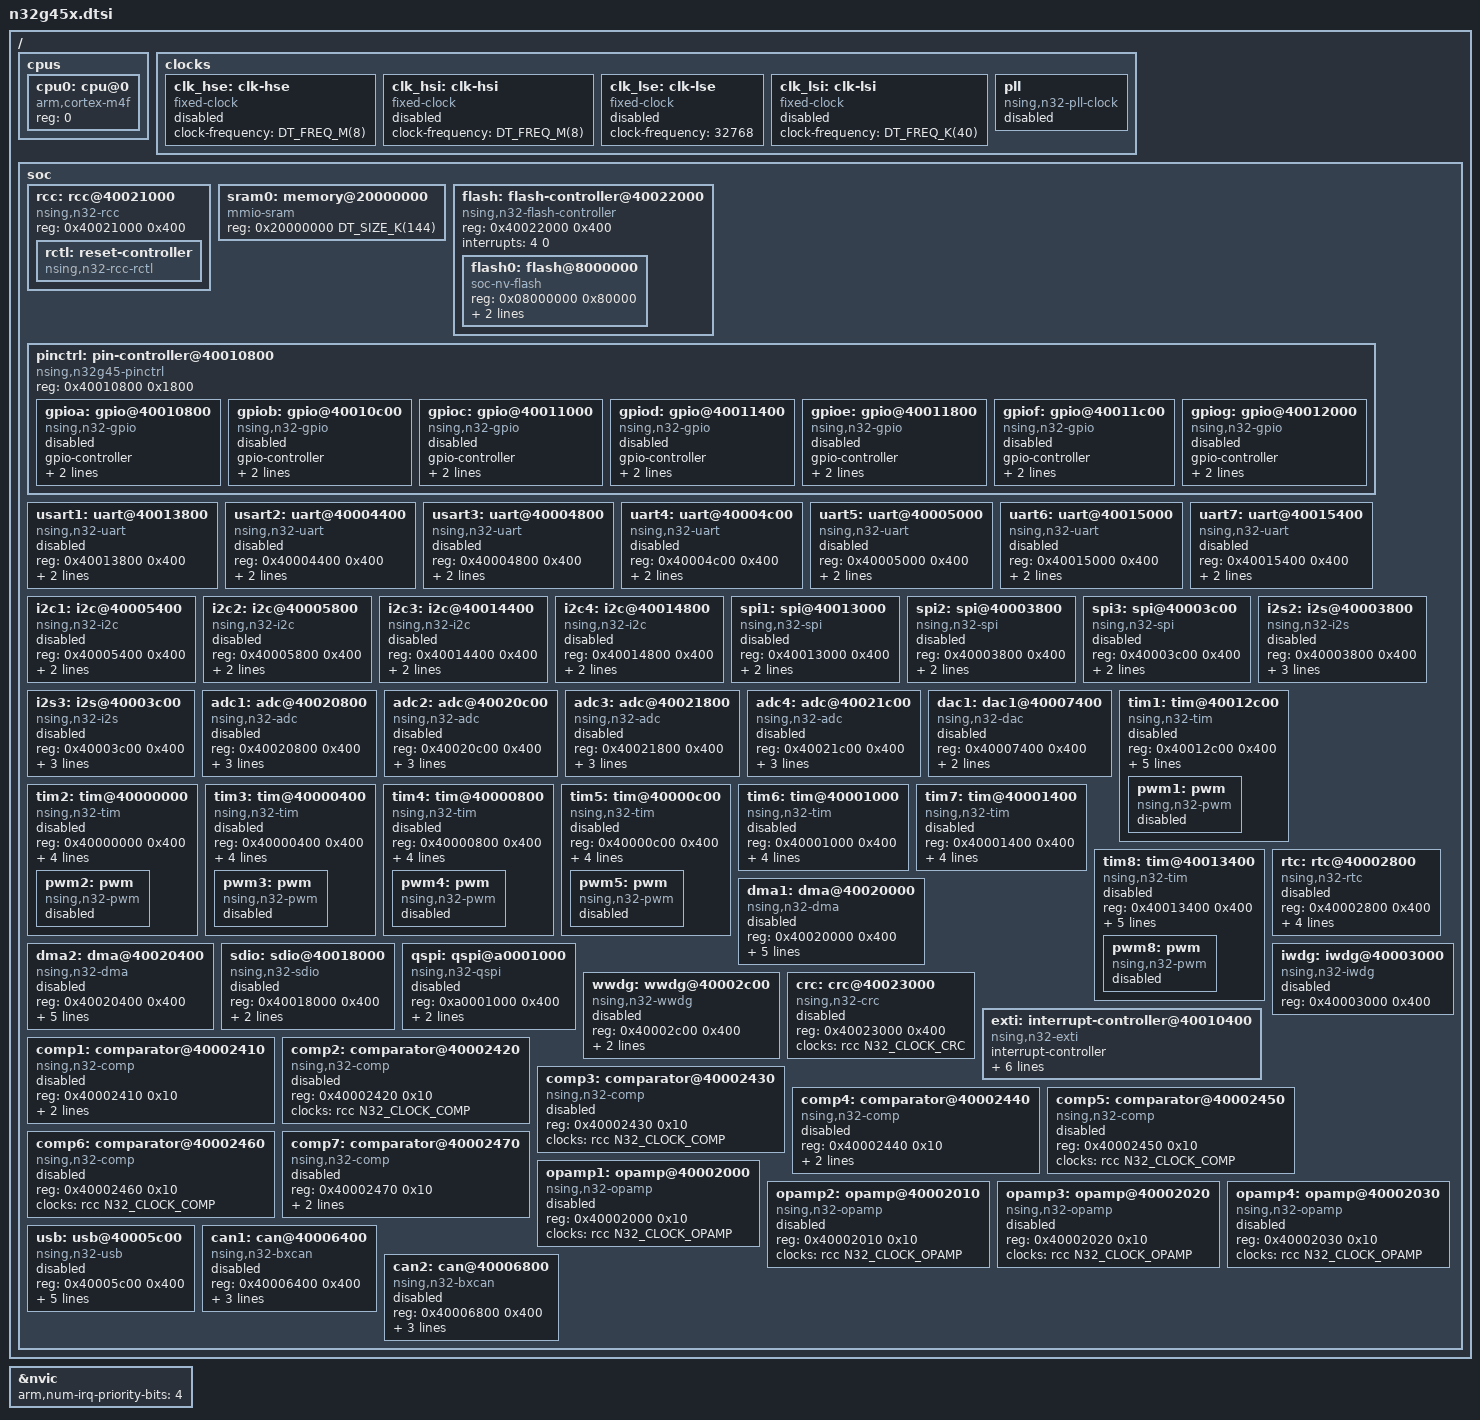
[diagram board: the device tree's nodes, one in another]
/*
 * Copyright (c) 2024 Nations Technologies
 * SPDX-License-Identifier: Apache-2.0
 *
 * N32G45x SoC devicetree, written from the peripheral definitions in
 * modules/hal/nsing.
 *
 * The base addresses and interrupt numbers come from the HAL's n32g45x.h,
 * the clock bits from n32_clock.h. The following peripherals are described:
 * I2C1-4, SPI1-3, ADC1-4, TIM1-8, DMA1-2, DAC, CAN1-2, RTC, SDIO, DVP, ETH,
 * QSPI, IWDG, WWDG, BKP, PWR, CRC, EXTI, COMP, OPAMP, TSC, RCC, FLASH, SRAM,
 * GPIOA-G and the USART/UART instances.
 *
 * TIM, DMA, RTC, SDIO, DVP, ETH, QSPI, IWDG, WWDG, BKP, PWR, CRC, EXTI and
 * TSC have no Zephyr driver yet, so their nodes are kept in block comments
 * until one exists. The COMP (7 instances) and OPAMP (4 instances) drivers
 * live in drivers/comparator and drivers/opamp.
 */

#include <mem.h>
#include <freq.h>
#include <arm/armv7-m.dtsi>
#include <zephyr/dt-bindings/gpio/gpio.h>
#include <zephyr/dt-bindings/i2c/i2c.h>
#include <zephyr/dt-bindings/clock/n32_clock.h>
#include <zephyr/dt-bindings/dma/n32_dma.h>
#include <zephyr/dt-bindings/reset/n32g45x-reset.h>

/ {

	cpus {
		#address-cells = <1>;
		#size-cells = <0>;

		cpu0: cpu@0 {
			device_type = "cpu";
			compatible = "arm,cortex-m4f";
			reg = <0>;
		};
	};

	clocks {
		clk_hse: clk-hse {
			#clock-cells = <0>;
			compatible = "fixed-clock";
			clock-frequency = <DT_FREQ_M(8)>;
			status = "disabled";
		};

		clk_hsi: clk-hsi {
			#clock-cells = <0>;
			compatible = "fixed-clock";
			clock-frequency = <DT_FREQ_M(8)>;
			status = "disabled";
		};

		clk_lse: clk-lse {
			#clock-cells = <0>;
			compatible = "fixed-clock";
			clock-frequency = <32768>;
			status = "disabled";
		};

		clk_lsi: clk-lsi {
			#clock-cells = <0>;
			compatible = "fixed-clock";
			clock-frequency = <DT_FREQ_K(40)>;
			status = "disabled";
		};

		pll: pll {
			#clock-cells = <0>;
			compatible = "nsing,n32-pll-clock";
			status = "disabled";
		};
	};

	soc {
		rcc: rcc@40021000 {
			compatible = "nsing,n32-rcc";
			#clock-cells = <1>;
			reg = <0x40021000 0x400>;

			rctl: reset-controller {
				compatible = "nsing,n32-rcc-rctl";
				#reset-cells = <1>;
			};
		};

		sram0: memory@20000000 {
			compatible = "mmio-sram";
			reg = <0x20000000 DT_SIZE_K(144)>;
		};

		flash: flash-controller@40022000 {
			compatible = "nsing,n32-flash-controller";
			reg = <0x40022000 0x400>;
			interrupts = <4 0>;
			#address-cells = <1>;
			#size-cells = <1>;

			flash0: flash@8000000 {
				compatible = "soc-nv-flash";
				reg = <0x08000000 0x80000>;
				write-block-size = <4>;
				erase-block-size = <0x800>;
			};
		};

		pinctrl: pin-controller@40010800 {
			compatible = "nsing,n32g45-pinctrl";
			reg = <0x40010800 0x1800>;
			#address-cells = <1>;
			#size-cells = <1>;

			gpioa: gpio@40010800 {
				compatible = "nsing,n32-gpio";
				gpio-controller;
				#gpio-cells = <2>;
				reg = <0x40010800 0x400>;
				clocks = <&rcc N32_CLOCK_GPIOA>;
				status = "disabled";
			};

			gpiob: gpio@40010c00 {
				compatible = "nsing,n32-gpio";
				gpio-controller;
				#gpio-cells = <2>;
				reg = <0x40010c00 0x400>;
				clocks = <&rcc N32_CLOCK_GPIOB>;
				status = "disabled";
			};

			gpioc: gpio@40011000 {
				compatible = "nsing,n32-gpio";
				gpio-controller;
				#gpio-cells = <2>;
				reg = <0x40011000 0x400>;
				clocks = <&rcc N32_CLOCK_GPIOC>;
				status = "disabled";
			};

			gpiod: gpio@40011400 {
				compatible = "nsing,n32-gpio";
				gpio-controller;
				#gpio-cells = <2>;
				reg = <0x40011400 0x400>;
				clocks = <&rcc N32_CLOCK_GPIOD>;
				status = "disabled";
			};

			gpioe: gpio@40011800 {
				compatible = "nsing,n32-gpio";
				gpio-controller;
				#gpio-cells = <2>;
				reg = <0x40011800 0x400>;
				clocks = <&rcc N32_CLOCK_GPIOE>;
				status = "disabled";
			};

			gpiof: gpio@40011c00 {
				compatible = "nsing,n32-gpio";
				gpio-controller;
				#gpio-cells = <2>;
				reg = <0x40011c00 0x400>;
				clocks = <&rcc N32_CLOCK_GPIOF>;
				status = "disabled";
			};

			gpiog: gpio@40012000 {
				compatible = "nsing,n32-gpio";
				gpio-controller;
				#gpio-cells = <2>;
				reg = <0x40012000 0x400>;
				clocks = <&rcc N32_CLOCK_GPIOG>;
				status = "disabled";
			};
		};

		usart1: uart@40013800 {
			compatible = "nsing,n32-uart";
			reg = <0x40013800 0x400>;
			clocks = <&rcc N32_CLOCK_USART1>;
			interrupts = <37 0>;
			status = "disabled";
		};

		usart2: uart@40004400 {
			compatible = "nsing,n32-uart";
			reg = <0x40004400 0x400>;
			clocks = <&rcc N32_CLOCK_USART2>;
			interrupts = <38 0>;
			status = "disabled";
		};

		usart3: uart@40004800 {
			compatible = "nsing,n32-uart";
			reg = <0x40004800 0x400>;
			clocks = <&rcc N32_CLOCK_USART3>;
			interrupts = <39 0>;
			status = "disabled";
		};

		uart4: uart@40004c00 {
			compatible = "nsing,n32-uart";
			reg = <0x40004c00 0x400>;
			clocks = <&rcc N32_CLOCK_UART4>;
			interrupts = <52 0>;
			status = "disabled";
		};

		uart5: uart@40005000 {
			compatible = "nsing,n32-uart";
			reg = <0x40005000 0x400>;
			clocks = <&rcc N32_CLOCK_UART5>;
			interrupts = <53 0>;
			status = "disabled";
		};

		uart6: uart@40015000 {
			compatible = "nsing,n32-uart";
			reg = <0x40015000 0x400>;
			clocks = <&rcc N32_CLOCK_UART6>;
			interrupts = <74 0>;
			status = "disabled";
		};

		uart7: uart@40015400 {
			compatible = "nsing,n32-uart";
			reg = <0x40015400 0x400>;
			clocks = <&rcc N32_CLOCK_UART7>;
			interrupts = <75 0>;
			status = "disabled";
		};

		i2c1: i2c@40005400 {
			compatible = "nsing,n32-i2c";
			#address-cells = <1>;
			#size-cells = <0>;
			reg = <0x40005400 0x400>;
			clocks = <&rcc N32_CLOCK_I2C1>;
			interrupts = <31 0>, <32 0>;
			interrupt-names = "event", "error";
			status = "disabled";
		};

		i2c2: i2c@40005800 {
			compatible = "nsing,n32-i2c";
			#address-cells = <1>;
			#size-cells = <0>;
			reg = <0x40005800 0x400>;
			clocks = <&rcc N32_CLOCK_I2C2>;
			interrupts = <33 0>, <34 0>;
			interrupt-names = "event", "error";
			status = "disabled";
		};

		i2c3: i2c@40014400 {
			compatible = "nsing,n32-i2c";
			#address-cells = <1>;
			#size-cells = <0>;
			reg = <0x40014400 0x400>;
			clocks = <&rcc N32_CLOCK_I2C3>;
			interrupts = <70 0>, <71 0>;
			interrupt-names = "event", "error";
			status = "disabled";
		};

		i2c4: i2c@40014800 {
			compatible = "nsing,n32-i2c";
			#address-cells = <1>;
			#size-cells = <0>;
			reg = <0x40014800 0x400>;
			clocks = <&rcc N32_CLOCK_I2C4>;
			interrupts = <72 0>, <73 0>;
			interrupt-names = "event", "error";
			status = "disabled";
		};

		spi1: spi@40013000 {
			compatible = "nsing,n32-spi";
			#address-cells = <1>;
			#size-cells = <0>;
			reg = <0x40013000 0x400>;
			clocks = <&rcc N32_CLOCK_SPI1>;
			interrupts = <35 5>;
			status = "disabled";
		};

		spi2: spi@40003800 {
			compatible = "nsing,n32-spi";
			#address-cells = <1>;
			#size-cells = <0>;
			reg = <0x40003800 0x400>;
			clocks = <&rcc N32_CLOCK_SPI2>;
			interrupts = <36 0>;
			status = "disabled";
		};

		spi3: spi@40003c00 {
			compatible = "nsing,n32-spi";
			#address-cells = <1>;
			#size-cells = <0>;
			reg = <0x40003c00 0x400>;
			clocks = <&rcc N32_CLOCK_SPI3>;
			interrupts = <51 0>;
			status = "disabled";
		};

		/*
		 * The I2S blocks are the same hardware as spi2/spi3 in I2S mode,
		 * so these deliberately share their unit addresses: a board
		 * enables one node of a given instance or the other, never both.
		 * SPI1 has no I2S mode.
		 *
		 * The DMA request cell is 0, which leaves each channel on its
		 * hardwired mapping -- what the vendor examples rely on. The
		 * channel cell is 0-based, so dma1 channels 3 and 4 are the
		 * vendor's DMA1_CH4 and DMA1_CH5.
		 */
		i2s2: i2s@40003800 {
			compatible = "nsing,n32-i2s";
			reg = <0x40003800 0x400>;
			clocks = <&rcc N32_CLOCK_SPI2>;
			interrupts = <36 0>;
			dmas = <&dma1 3 0 0>, <&dma1 4 0 0>;
			dma-names = "rx", "tx";
			status = "disabled";
		};

		i2s3: i2s@40003c00 {
			compatible = "nsing,n32-i2s";
			reg = <0x40003c00 0x400>;
			clocks = <&rcc N32_CLOCK_SPI3>;
			interrupts = <51 0>;
			dmas = <&dma2 0 0 0>, <&dma2 1 0 0>;
			dma-names = "rx", "tx";
			status = "disabled";
		};

		adc1: adc@40020800 {
			compatible = "nsing,n32-adc";
			reg = <0x40020800 0x400>;
			clocks = <&rcc N32_CLOCK_ADC1>;
			interrupts = <18 0>;
			#io-channel-cells = <1>;
			channels = <16>;
			status = "disabled";
		};

		adc2: adc@40020c00 {
			compatible = "nsing,n32-adc";
			reg = <0x40020c00 0x400>;
			clocks = <&rcc N32_CLOCK_ADC2>;
			interrupts = <18 0>;
			#io-channel-cells = <1>;
			channels = <16>;
			status = "disabled";
		};

		adc3: adc@40021800 {
			compatible = "nsing,n32-adc";
			reg = <0x40021800 0x400>;
			clocks = <&rcc N32_CLOCK_ADC3>;
			interrupts = <47 0>;
			#io-channel-cells = <1>;
			channels = <16>;
			status = "disabled";
		};

		adc4: adc@40021c00 {
			compatible = "nsing,n32-adc";
			reg = <0x40021c00 0x400>;
			clocks = <&rcc N32_CLOCK_ADC4>;
			interrupts = <47 0>;
			#io-channel-cells = <1>;
			channels = <16>;
			status = "disabled";
		};

		dac1: dac1@40007400 {
			compatible = "nsing,n32-dac";
			reg = <0x40007400 0x400>;
			clocks = <&rcc N32_CLOCK_DAC>;
			num-channels = <2>;
			#io-channel-cells = <1>;
			status = "disabled";

		};

		/* TIM1 and TIM8 are advanced timers; TIM2-TIM5 are general-purpose. */
		tim1: tim@40012c00 {
			compatible = "nsing,n32-tim";
			reg = <0x40012c00 0x400>;
			clocks = <&rcc N32_CLOCK_TIM1>;
			interrupts = <25 0>, <24 0>, <26 0>, <27 0>;
			interrupt-names = "up", "brk", "trg_com", "cc";
			prescaler = <0>;
			channels = <4>;
			advanced;
			status = "disabled";
			pwm1: pwm {
				compatible = "nsing,n32-pwm";
				#pwm-cells = <3>;
				status = "disabled";
			};
		};
		tim2: tim@40000000 {
			compatible = "nsing,n32-tim";
			reg = <0x40000000 0x400>;
			clocks = <&rcc N32_CLOCK_TIM2>;
			interrupts = <28 0>;
			prescaler = <0>;
			channels = <4>;
			status = "disabled";
			pwm2: pwm {
				compatible = "nsing,n32-pwm";
				#pwm-cells = <3>;
				status = "disabled";
			};
		};
		tim3: tim@40000400 {
			compatible = "nsing,n32-tim";
			reg = <0x40000400 0x400>;
			clocks = <&rcc N32_CLOCK_TIM3>;
			interrupts = <29 0>;
			prescaler = <0>;
			channels = <4>;
			status = "disabled";
			pwm3: pwm {
				compatible = "nsing,n32-pwm";
				#pwm-cells = <3>;
				status = "disabled";
			};
		};
		tim4: tim@40000800 {
			compatible = "nsing,n32-tim";
			reg = <0x40000800 0x400>;
			clocks = <&rcc N32_CLOCK_TIM4>;
			interrupts = <30 0>;
			prescaler = <0>;
			channels = <4>;
			status = "disabled";
			pwm4: pwm {
				compatible = "nsing,n32-pwm";
				#pwm-cells = <3>;
				status = "disabled";
			};
		};
		tim5: tim@40000c00 {
			compatible = "nsing,n32-tim";
			reg = <0x40000c00 0x400>;
			clocks = <&rcc N32_CLOCK_TIM5>;
			interrupts = <50 0>;
			prescaler = <0>;
			channels = <4>;
			status = "disabled";
			pwm5: pwm {
				compatible = "nsing,n32-pwm";
				#pwm-cells = <3>;
				status = "disabled";
			};
		};
		tim6: tim@40001000 {
			compatible = "nsing,n32-tim";
			reg = <0x40001000 0x400>;
			clocks = <&rcc N32_CLOCK_TIM6>;
			interrupts = <54 0>;
			prescaler = <0>;
			channels = <0>;
			status = "disabled";
		};
		tim7: tim@40001400 {
			compatible = "nsing,n32-tim";
			reg = <0x40001400 0x400>;
			clocks = <&rcc N32_CLOCK_TIM7>;
			interrupts = <55 0>;
			prescaler = <0>;
			channels = <0>;
			status = "disabled";
		};
		tim8: tim@40013400 {
			compatible = "nsing,n32-tim";
			reg = <0x40013400 0x400>;
			clocks = <&rcc N32_CLOCK_TIM8>;
			interrupts = <44 0>, <43 0>, <45 0>, <46 0>;
			interrupt-names = "up", "brk", "trg_com", "cc";
			prescaler = <0>;
			channels = <4>;
			advanced;
			status = "disabled";
			pwm8: pwm {
				compatible = "nsing,n32-pwm";
				#pwm-cells = <3>;
				status = "disabled";
			};
		};

		/* Interrupt order is channel order: the driver connects IRQ_BY_IDX(n)
		 * to channel n.
		 */
		dma1: dma@40020000 {
			compatible = "nsing,n32-dma";
			reg = <0x40020000 0x400>;
			clocks = <&rcc N32_CLOCK_DMA1>;
			interrupts = <11 0>, <12 0>, <13 0>, <14 0>, <15 0>, <16 0>, <17 0>, <76 0>;
			#dma-cells = <3>;
			dma-channels = <8>;
			nsing,mem2mem;
			status = "disabled";
		};

		dma2: dma@40020400 {
			compatible = "nsing,n32-dma";
			reg = <0x40020400 0x400>;
			clocks = <&rcc N32_CLOCK_DMA2>;
			interrupts = <56 0>, <57 0>, <58 0>, <59 0>, <60 0>, <68 0>, <69 0>, <77 0>;
			#dma-cells = <3>;
			dma-channels = <8>;
			nsing,mem2mem;
			status = "disabled";
		};

		rtc: rtc@40002800 {
			compatible = "nsing,n32-rtc";
			reg = <0x40002800 0x400>;
			interrupts = <41 0>;
			/* Backup-domain access gates: BKP + PWR on APB1. */
			clocks = <&rcc N32_CLOCK_BKP>, <&rcc N32_CLOCK_PWR>;
			alarms-count = <2>;
			alrm-exti-line = <17>;
			status = "disabled";
		};

	/* ---- Other peripherals, each still needs a binding ---- */

		sdio: sdio@40018000 {
			compatible = "nsing,n32-sdio";
			reg = <0x40018000 0x400>;
			clocks = <&rcc N32_CLOCK_SDIO>;
			interrupts = <49 0>;
			status = "disabled";
		};

/*
 *         dvp: dvp@40014c00 {
 *             compatible = "nsing,n32-dvp";
 *             reg = <0x40014c00 0x400>;
 *             clocks = <&rcc N32_CLOCK_DVP>;
 *             interrupts = <78 0>;
 *             status = "disabled";
 *         };
 */

/*
 *         eth: eth@40028000 {
 *             compatible = "nsing,n32-eth";
 *             reg = <0x40028000 0x400>;
 *             clocks = <&rcc N32_CLOCK_ETH>;
 *             interrupts = <61 0>;
 *             status = "disabled";
 *         };
 */

		/*
		 * The transmit channel only. The driver hands a packet that is
		 * longer than the FIFO to it, because a frame pushed by the CPU
		 * costs more time than one the core shifts; the receive side
		 * needs no channel.
		 *
		 * The request cell is not optional here, unlike the SPI/I2S nodes
		 * above whose channels do have a hardwired request. Nothing on
		 * this part drives a DMA request from the QSPI unless it is
		 * remapped, so a zero in that cell leaves the channel triggered by
		 * whatever else its default mapping carries -- which is what the
		 * vendor examples avoid by asking for the same code explicitly.
		 * The channel is then a channel like any other: CHSEL and the
		 * controller wide CHMAPEN bit are what route the request, so seven
		 * is only a nod to the vendor, which transmits on DMA2_CH7.
		 */
		qspi: qspi@a0001000 {
			compatible = "nsing,n32-qspi";
			reg = <0xa0001000 0x400>;
			clocks = <&rcc N32_CLOCK_QSPI>;
			dmas = <&dma2 7 N32_DMA2_REQ_QSPI_TX 0>;
			dma-names = "tx";
			#address-cells = <1>;
			#size-cells = <0>;
			status = "disabled";
		};

		iwdg: iwdg@40003000 {
			compatible = "nsing,n32-iwdg";
			reg = <0x40003000 0x400>;
			status = "disabled";
		};

		wwdg: wwdg@40002c00 {
			compatible = "nsing,n32-wwdg";
			reg = <0x40002c00 0x400>;
			clocks = <&rcc N32_CLOCK_WWDG>;
			interrupts = <0 0>;
			status = "disabled";
		};

/*
 *         bkp: bkp@40006c00 {
 *             compatible = "nsing,n32-bkp";
 *             reg = <0x40006c00 0x400>;
 *             clocks = <&rcc N32_CLOCK_BKP>;
 *             status = "disabled";
 *         };
 */

/*
 *         pwr: pwr@40007000 {
 *             compatible = "nsing,n32-pwr";
 *             reg = <0x40007000 0x400>;
 *             clocks = <&rcc N32_CLOCK_PWR>;
 *             status = "disabled";
 *         };
 */

	crc: crc@40023000 {
		compatible = "nsing,n32-crc";
		reg = <0x40023000 0x400>;
		clocks = <&rcc N32_CLOCK_CRC>;
		status = "disabled";
	};

		/* EXTI shares the AFIO clock and hangs off APB2. */
		exti: interrupt-controller@40010400 {
			compatible = "nsing,n32-exti";
			interrupt-controller;
			#interrupt-cells = <1>;
			reg = <0x40010400 0x400>;
			num-lines = <16>;
			interrupts = <6 0>, <7 0>, <8 0>, <9 0>,
				     <10 0>, <23 0>, <40 0>;
			interrupt-names = "line0", "line1", "line2", "line3",
					  "line4", "line5-9", "line10-15";
			line-ranges = <0 1>, <1 1>, <2 1>, <3 1>,
				      <4 1>, <5 5>, <10 6>;
		};

		/* One device node per N32G45x COMP / OPAMP instance, for the generic
		 * Zephyr comparator and opamp subsystems. Base addresses: COMP at
		 * 0x40002400 (each channel's CTRL at +0x10), OPAMP at 0x40002000
		 * (each channel's CS at +0x10). The COMP interrupt lines are shared:
		 * COMP1/2/3 -> 82, COMP4/5/6 -> 83, COMP7 -> 84. Only one comparator
		 * per group can use the interrupt callback at a time, so interrupts
		 * are declared on the first instance of each group only.
		 */
		comp1: comparator@40002410 {
			compatible = "nsing,n32-comp";
			reg = <0x40002410 0x10>;
			clocks = <&rcc N32_CLOCK_COMP>;
			interrupts = <82 0>;
			status = "disabled";
		};
		comp2: comparator@40002420 {
			compatible = "nsing,n32-comp";
			reg = <0x40002420 0x10>;
			clocks = <&rcc N32_CLOCK_COMP>;
			status = "disabled";
		};
		comp3: comparator@40002430 {
			compatible = "nsing,n32-comp";
			reg = <0x40002430 0x10>;
			clocks = <&rcc N32_CLOCK_COMP>;
			status = "disabled";
		};
		comp4: comparator@40002440 {
			compatible = "nsing,n32-comp";
			reg = <0x40002440 0x10>;
			clocks = <&rcc N32_CLOCK_COMP>;
			interrupts = <83 0>;
			status = "disabled";
		};
		comp5: comparator@40002450 {
			compatible = "nsing,n32-comp";
			reg = <0x40002450 0x10>;
			clocks = <&rcc N32_CLOCK_COMP>;
			status = "disabled";
		};
		comp6: comparator@40002460 {
			compatible = "nsing,n32-comp";
			reg = <0x40002460 0x10>;
			clocks = <&rcc N32_CLOCK_COMP>;
			status = "disabled";
		};
		comp7: comparator@40002470 {
			compatible = "nsing,n32-comp";
			reg = <0x40002470 0x10>;
			clocks = <&rcc N32_CLOCK_COMP>;
			interrupts = <84 0>;
			status = "disabled";
		};
		opamp1: opamp@40002000 {
			compatible = "nsing,n32-opamp";
			reg = <0x40002000 0x10>;
			clocks = <&rcc N32_CLOCK_OPAMP>;
			status = "disabled";
		};
		opamp2: opamp@40002010 {
			compatible = "nsing,n32-opamp";
			reg = <0x40002010 0x10>;
			clocks = <&rcc N32_CLOCK_OPAMP>;
			status = "disabled";
		};
		opamp3: opamp@40002020 {
			compatible = "nsing,n32-opamp";
			reg = <0x40002020 0x10>;
			clocks = <&rcc N32_CLOCK_OPAMP>;
			status = "disabled";
		};
		opamp4: opamp@40002030 {
			compatible = "nsing,n32-opamp";
			reg = <0x40002030 0x10>;
			clocks = <&rcc N32_CLOCK_OPAMP>;
			status = "disabled";
		};


/*
 *         tsc: tsc@40003400 {
 *             compatible = "nsing,n32-tsc";
 *             reg = <0x40003400 0x400>;
 *             clocks = <&rcc N32_CLOCK_TSC>;
 *             interrupts = <81 0>;
 *             status = "disabled";
 *         };
 */

		/* USB FS device controller.  Shares the PMA SRAM (0x40006000)
		 * and the interrupt line with CAN1; the two must not be used
		 * at the same time.
		 */
		usb: usb@40005c00 {
			compatible = "nsing,n32-usb";
			reg = <0x40005c00 0x400>;
			interrupts = <20 0>;
			interrupt-names = "usb";
			num-bidir-endpoints = <8>;
			ram-size = <512>;
			maximum-speed = "full-speed";
			status = "disabled";
			clocks = <&rcc N32_CLOCK_USB>;
		};

		can1: can@40006400 {
			compatible = "nsing,n32-bxcan";
			reg = <0x40006400 0x400>;
			clocks = <&rcc N32_CLOCK_CAN1>;
			interrupts = <20 0>, <19 0>, <22 0>;
			interrupt-names = "rx", "tx", "sce";
			sample-point = <875>;
			status = "disabled";
		};

		can2: can@40006800 {
			compatible = "nsing,n32-bxcan";
			reg = <0x40006800 0x400>;
			clocks = <&rcc N32_CLOCK_CAN2>;
			interrupts = <64 0>, <63 0>, <66 0>;
			interrupt-names = "rx", "tx", "sce";
			bitrate = <500000>;
			status = "disabled";
		};


	};
};

&nvic {
	arm,num-irq-priority-bits = <4>;
};
